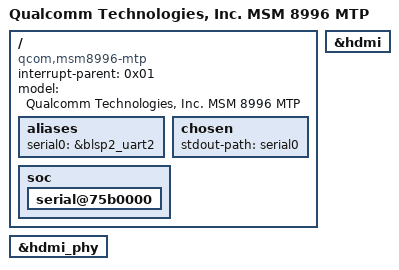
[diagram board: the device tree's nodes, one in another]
/dts-v1/;

#include "msm8996.dtsi"

/ {
	interrupt-parent = <0x01>;
	#address-cells = <0x02>;
	#size-cells = <0x02>;
	model = "Qualcomm Technologies, Inc. MSM 8996 MTP";
	compatible = "qcom,msm8996-mtp";

	aliases {
		serial0 = &blsp2_uart2;
	};

	chosen {
		stdout-path = "serial0";
	};

	soc {
		serial@75b0000 {
			status = "okay";
		};
	};
};

&hdmi {
	status = "okay";
};

&hdmi_phy {
	status = "okay";
};
